# GD32A72_A74x register map
File version: 1.0
CPU: CM7 r2p1, little endian, MPU, FPU, DSP, 4 interrupt priority bits
Registers are 32-bit, read-write, reset 0x0 unless marked. A register's access mark holds for its fields unless they carry their own. Offsets are from the block's base; [hi:lo] are bit positions; {n}, {i} and the like mark numbered series; 'fields as' and 'values as' point back to an identical list.

## CAN0 — Controller area network
Base 0x40018000
Same registers: CAN1 0x40019000, CAN2 0x4001A000
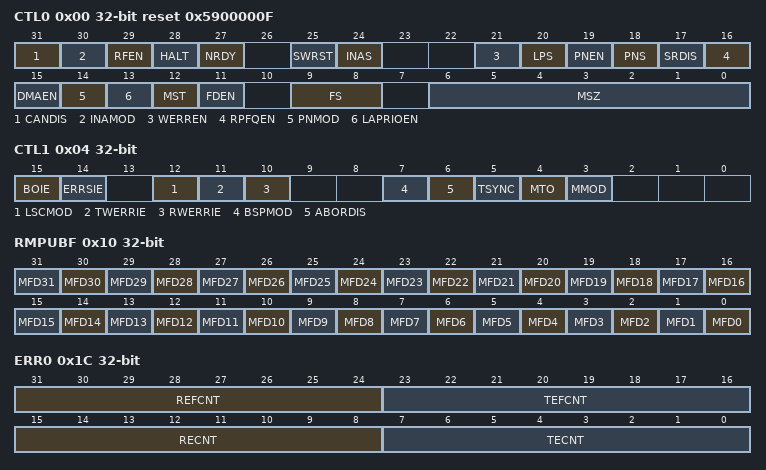
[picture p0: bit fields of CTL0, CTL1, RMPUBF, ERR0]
0x00 CTL0 access per field reset 0x5900000F — Control register 0
  [31] CANDIS rw — CAN disable
  [30] INAMOD rw — Inactive mode enable
  [29] RFEN rw — Rx FIFO enable
  [28] HALT rw — Halt CAN
  [27] NRDY ro — Not ready
  [25] SWRST rw — Software reset
  [24] INAS ro — Inactive mode state
  [21] WERREN rw — Error warning enable
  [20] LPS ro — Low power state
  [19] PNEN rw — Pretended Networking mode enable
  [18] PNS ro — Pretended Networking state
  [17] SRDIS rw — Self reception disable
  [16] RPFQEN rw — Rx private filters enable / Rx mailbox queue enable
  [15] DMAEN rw — DMA enable
  [14] PNMOD rw — Pretended Networking mode selection
  [13] LAPRIOEN rw — Local arbitration priority enable
  [12] MST rw — Mailbox stop transmission
  [11] FDEN rw — CAN FD operation enable
  [9:8] FS rw — Format selection
  [6:0] MSZ rw — Memory size
0x04 CTL1 — Control register 1
  [15] BOIE — Bus off interrupt enable
  [14] ERRSIE — Error summary interrupt enable
  [12] LSCMOD — Loopback and silent communication mode
  [11] TWERRIE — Tx error warning interrupt enable
  [10] RWERRIE — Rx error warning interrupt enable
  [7] BSPMOD — Bit sampling mode
  [6] ABORDIS — Automatic Bus off recovery not enable
  [5] TSYNC — Time synchronization enable
  [4] MTO — Mailbox transmission order
  [3] MMOD — Monitor mode
0x08 TIMER
  [15:0] CNT — Counter value
0x10 RMPUBF — Receive mailbox public filter register
  [n] MFD{n} (n=0..31) — Mailbox filter data {n}
0x1C ERR0 — Error register 0
  [31:24] REFCNT — Receive error counter for data phase of FD frames with BRS bit set
  [23:16] TEFCNT — Transmit error count for the data phase of FD frames with BRS bit set
  [15:8] RECNT — Receive error count defined by the CAN standard
  [7:0] TECNT — Transmit error count defined by the CAN standard
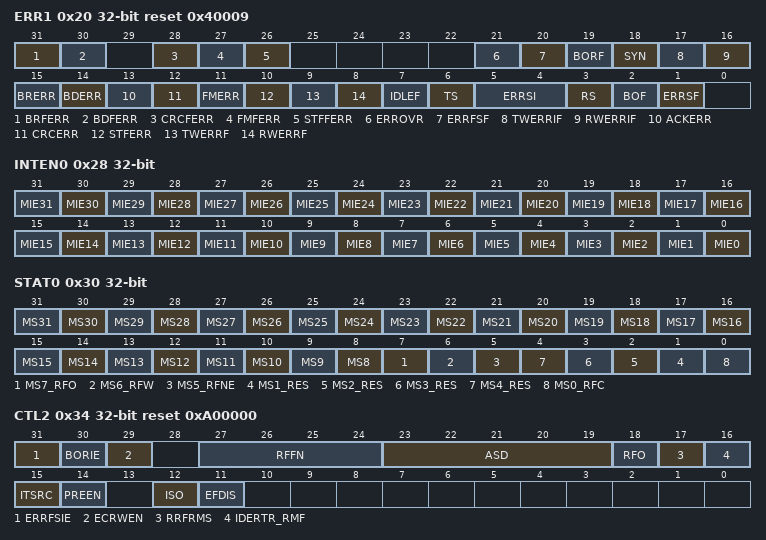
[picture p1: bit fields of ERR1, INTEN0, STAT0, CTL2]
0x20 ERR1 access per field reset 0x40009 — Error register 1
  [31] BRFERR rw — Bit recessive error in data phase of FD frames with the BRS bit set
  [30] BDFERR rw — Bit dominant error in data phase of FD frames with the BRS bit set
  [28] CRCFERR rw — CRC error in data phase of FD frames with the BRS bit set
  [27] FMFERR rw — Form error in data phase of FD frames with the BRS bit set
  [26] STFFERR rw — Stuff error in data phase of FD frames with the BRS bit set
  [21] ERROVR rw — Error overrun
  [20] ERRFSF rw — Error summary flag for data phase of FD frames with BRS bit set
  [19] BORF rw — Bus off recovery flag
  [18] SYN ro — Synchronization flag
  [17] TWERRIF rw — Tx error warning interrupt flag
  [16] RWERRIF rw — Rx error warning interrupt flag
  [15] BRERR rw — Bit recessive error for all format frames
  [14] BDERR rw — Bit dominant error for all format frames
  [13] ACKERR rw — ACK error
  [12] CRCERR rw — CRC error
  [11] FMERR rw — Form error
  [10] STFERR rw — Stuff error
  [9] TWERRF ro — Tx error warning flag
  [8] RWERRF ro — Rx error warning flag
  [7] IDLEF ro — IDLE flag
  [6] TS ro — Transmitting state
  [5:4] ERRSI ro — Error state indicator
  [3] RS ro — Receiving state
  [2] BOF rw — Bus off flag
  [1] ERRSF rw — Error summary flag
0x28 INTEN0 — Interrupt enable register 0
  [n] MIE{n} (n=0..31) — Message transmission and reception interrupt enable {n}
0x30 STAT0 — Status register 0
  [n] MS{n} (n=8..31) — Mailbox {n} state
  [7] MS7_RFO — Mailbox 7 state / Rx FIFO overflow
  [6] MS6_RFW — Mailbox 6 state / Rx FIFO warning
  [5] MS5_RFNE — Mailbox 5 state / Rx FIFO not empty
  [n] MS{n}_RES (n=1..4) — Mailbox {n} state / Reserved
  [0] MS0_RFC — Mailbox 0 state / Clear Rx FIFO bit
0x34 CTL2 reset 0xA00000 — Control register 2
  [31] ERRFSIE — Error summary interrupt enable bit for data phase of FD frames with BRS bit set
  [30] BORIE — Bus off recovery interrupt enable
  [29] ECRWEN — CAN_MERRCTL register write access enable
  [27:24] RFFN — Rx FIFO filter number
  [23:19] ASD — Arbitration start delay
  [18] RFO — Receive filter order
  [17] RRFRMS — Remote request frame is stored
  [16] IDERTR_RMF — IDE and RTR field filter type for Rx mailbox reception
  [15] ITSRC — Internal counter source
  [14] PREEN — Protocol exception detection enable by CAN standard
  [12] ISO — ISO CAN FD
  [11] EFDIS — Edge filtering disable
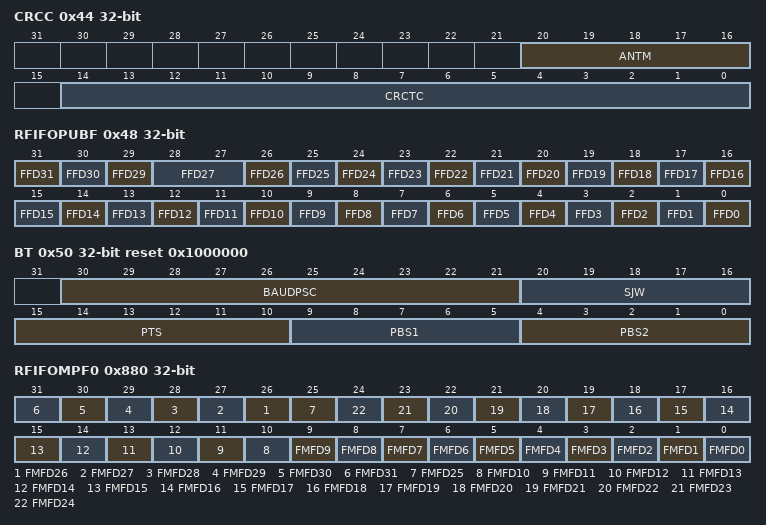
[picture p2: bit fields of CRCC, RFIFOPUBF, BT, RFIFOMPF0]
0x44 CRCC ro — CRC for classical frame register
  [20:16] ANTM — Associated number of mailbox for transmitting the CRCTC[14:0] value
  [14:0] CRCTC — Transmitted CRC value for classical frames
0x48 RFIFOPUBF — Receive FIFO public filter register
  [31] FFD31 — Rx FIFO filter data 31
  [30] FFD30 — Rx FIFO filter data 30
  [29] FFD29 — Rx FIFO filter data 29
  [28:27] FFD27 — Rx FIFO filter data 28
  [n] FFD{n} (n=0..26) — Rx FIFO filter data {n+1}
0x4C RFIFOIFMN ro — Receive FIFO identifier filter matching number register
  [8:0] IDFMN — Identifier filter matching number
0x50 BT reset 0x1000000 — Bit timing register
  [30:21] BAUDPSC — Baud rate prescaler
  [20:16] SJW — Resynchronization jump width
  [15:10] PTS — Propagation time segment
  [9:5] PBS1 — Phase buffer segment 1
  [4:0] PBS2 — Phase buffer segment 2
0x880 RFIFOMPF0 — Receive FIFO/mailbox private filter 0 register
  [n] FMFD{n} (n=26..31) — FIFO/mailbox filter data {n}
  [25] FMFD25 — FIFO/mailbox filter data 27
  [n] FMFD{n} (n=0..24) — FIFO/mailbox filter data {n}
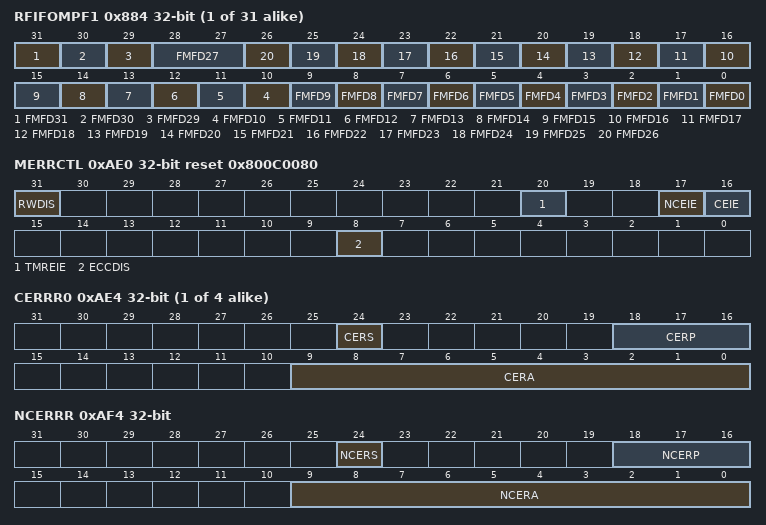
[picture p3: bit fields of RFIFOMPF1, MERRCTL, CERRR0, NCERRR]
{0x880+4i} RFIFOMPF{i} (i=1..31) — Receive FIFO/mailbox private filter {i} register
  [31] FMFD31 — FIFO/mailbox filter data 31
  [30] FMFD30 — FIFO/mailbox filter data 30
  [29] FMFD29 — FIFO/mailbox filter data 29
  [28:27] FMFD27 — FIFO/mailbox filter data 28
  [n] FMFD{n} (n=0..26) — FIFO/mailbox filter data {n+1}
0xAE0 MERRCTL reset 0x800C0080 — Memory error control register
  [31] RWDIS — CAN_MERRCTL register write access disable
  [20] TMREIE — TMR error interrupt enable
  [17] NCEIE — Noncorrectable error interrupt enable
  [16] CEIE — Correctable error interrupt enable
  [8] ECCDIS — Disable ECC
{0xAE4+4i} CERRR{i} access per field (i=0..3) — Correctable error record register {i}
  [24] CERS rw — Correctable error record status
  [18:16] CERP ro — Correctable error record access process
  [9:0] CERA ro — Correctable error record address
0xAF4 NCERRR access per field — Noncorrectable error record register
  [24] NCERS rw — Noncorrectable error record status
  [18:16] NCERP ro — Noncorrectable error record access process
  [9:0] NCERA ro — Noncorrectable error record address
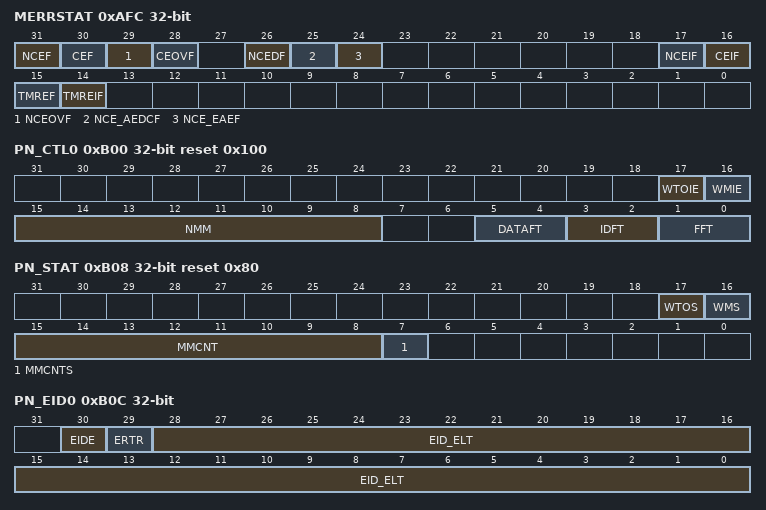
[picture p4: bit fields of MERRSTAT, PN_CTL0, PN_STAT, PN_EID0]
0xAFC MERRSTAT access per field — Memory error status register
  [31] NCEF rw — Noncorrectable error flag
  [30] CEF rw — Correctable error flag
  [29] NCEOVF rw — Noncorrectable error overflow flag
  [28] CEOVF rw — Correctable error overflow flag
  [26] NCEDF rw — Noncorrectable double bit error flag
  [25] NCE_AEDCF rw — Noncorrectable address EDC error flag
  [24] NCE_EAEF rw — Noncorrectable ECC after EDC error flag
  [17] NCEIF rw — Noncorrectable error interrupt flag
  [16] CEIF rw — Correctable error interrupt flag
  [15] TMREF rw — TMR error flag
  [14] TMREIF ro — TMR error interrupt flag
0xB00 PN_CTL0 reset 0x100 — Pretended Networking mode control register 0
  [17] WTOIE — Wakeup timeout interrupt enable
  [16] WMIE — Wakeup match interrupt enable
  [15:8] NMM — Number of messages matching times
  [5:4] DATAFT — DATA field filtering type in Pretended Networking mode
  [3:2] IDFT — ID field filtering type in Pretended Networking mode
  [1:0] FFT — Frame filtering type in Pretended Networking mode
0xB04 PN_TO — Pretended Networking mode timeout register
  [15:0] WTO — Wakeup timeout
0xB08 PN_STAT access per field reset 0x80 — Pretended Networking mode status register
  [17] WTOS rw — Wakeup timeout flag status
  [16] WMS rw — Wakeup match flag status
  [15:8] MMCNT ro — Matching message counter in Pretended Networking mode
  [7] MMCNTS ro — Matching message counter state
0xB0C PN_EID0 — Pretended Networking mode expected identifier 0 register
  [30] EIDE — Expected IDE in Pretended Networking mode
  [29] ERTR — Expected RTR in Pretended Networking mode
  [28:0] EID_ELT — Expected ID field / expected ID low threshold in Pretended Networking mode
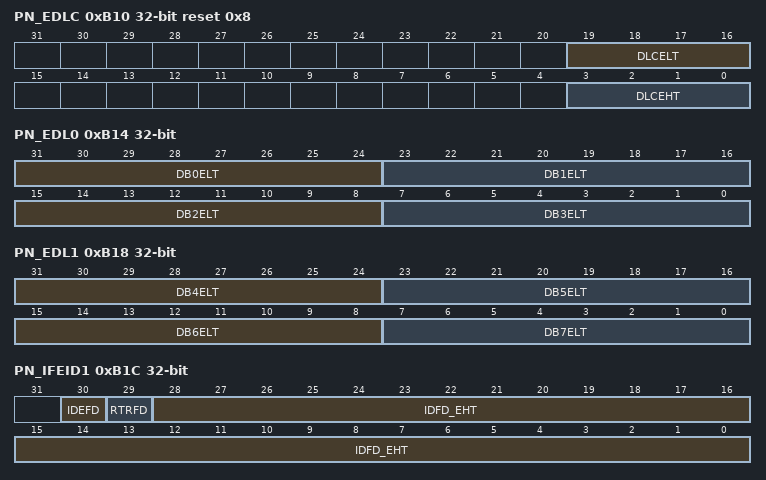
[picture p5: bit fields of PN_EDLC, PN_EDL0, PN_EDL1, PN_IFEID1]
0xB10 PN_EDLC reset 0x8 — Pretended Networking mode expected DLC register
  [19:16] DLCELT — DLC expected low threshold in Pretended Networking mode
  [3:0] DLCEHT — DLC expected high threshold in Pretended Networking mode
0xB14 PN_EDL0 — Pretended Networking mode expected data low 0 register
  [31-8n:24-8n] DB{n}ELT (n=0..3) — Data byte {n} expected low threshold in Pretended Networking mode
0xB18 PN_EDL1 — Pretended Networking mode expected data low 1 register
  [63-8n:56-8n] DB{n}ELT (n=4..7) — Data byte {n} expected low threshold in Pretended Networking mode
0xB1C PN_IFEID1 — Pretended Networking mode identifier filter / expected identifier 1 register
  [30] IDEFD — IDE filter data in Pretended Networking mode
  [29] RTRFD — RTR filter data in Pretended Networking mode
  [28:0] IDFD_EHT — ID filter data / ID expected high threshold in Pretended Networking mode
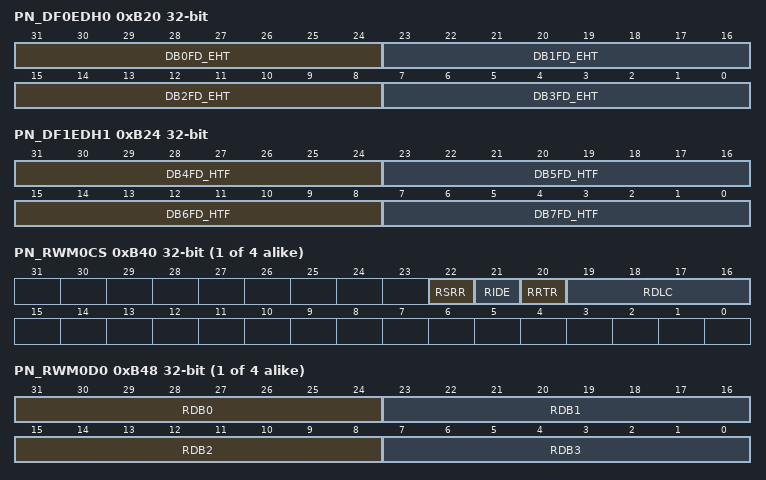
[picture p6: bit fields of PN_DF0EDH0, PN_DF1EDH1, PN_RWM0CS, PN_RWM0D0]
0xB20 PN_DF0EDH0 — Pretended Networking mode data 0 filter / expected data high 0 register
  [31:24] DB0FD_EHT — Data byte 0 filter data / Data byte 0 expected high threshold in Pretended Networking mode
  [23:16] DB1FD_EHT — Data byte 1 filter data / Data byte 1 expected high threshold in Pretended Networking mode
  [15:8] DB2FD_EHT — Data byte 2 filter data / Data byte 2 expected high threshold in Pretended Networking mode
  [7:0] DB3FD_EHT — Data byte 3 filter data / Data byte 2 expected high threshold in Pretended Networking mode
0xB24 PN_DF1EDH1 — Pretended Networking mode data 1 filter / expected data high 1 register
  [63-8n:56-8n] DB{n}FD_HTF (n=4..7) — Data byte {n} filter data / Data byte {n} expected high threshold in Pretended Networking mode
{0xB40+0x10*i} PN_RWM{i}CS ro (i=0..3) — Pretended Networking mode received wakeup mailbox {i} control status information register
  [22] RSRR — Received SRR bit
  [21] RIDE — Received IDE bit
  [20] RRTR — Received RTR bit
  [19:16] RDLC — Received DLC bits
{0xB44+0x10*i} PN_RWM{i}I ro (i=0..3) — Pretended Networking mode received wakeup mailbox {i} identifier register
  [28:0] RID — Received ID bits
{0xB48+0x10*i} PN_RWM{i}D0 ro (i=0..3) — Pretended Networking mode received wakeup mailbox {i} data 0 register
  [31-8n:24-8n] RDB{n} (n=0..3) — Received data byte {n}
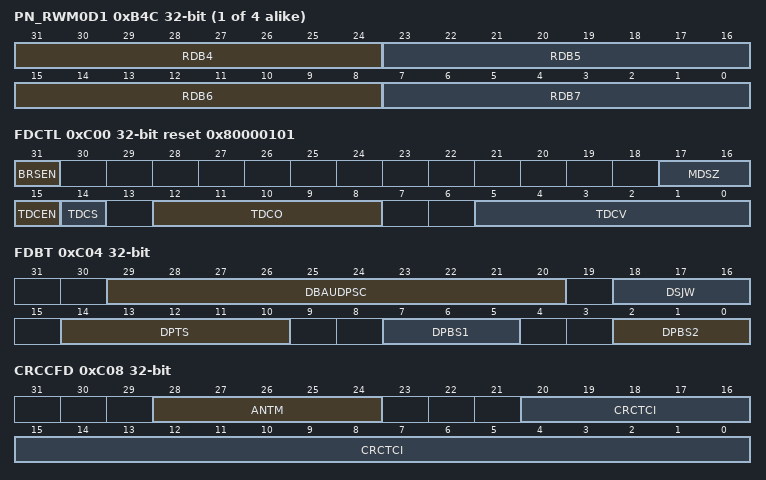
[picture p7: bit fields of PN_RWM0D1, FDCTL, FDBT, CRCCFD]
{0xB4C+0x10*i} PN_RWM{i}D1 ro (i=0..3) — Pretended Networking mode received wakeup mailbox {i} data 1 register
  [63-8n:56-8n] RDB{n} (n=4..7) — Received data byte {n}
0xC00 FDCTL access per field reset 0x80000101 — FD control register
  [31] BRSEN rw — Bit rate of data switch enable
  [17:16] MDSZ rw — Mailbox data size
  [15] TDCEN rw — Transmitter delay compensation enable
  [14] TDCS rw — Transmitter delay compensation status
  [12:8] TDCO rw — Transmitter delay compensation offset
  [5:0] TDCV ro — Transmitter delay compensation value
0xC04 FDBT — FD bit timing register
  [29:20] DBAUDPSC — Baud rate prescaler for data bit time
  [18:16] DSJW — Resynchronization jump width for data bit time
  [14:10] DPTS — Propagation time segment for data bit time
  [7:5] DPBS1 — Phase buffer segment 1 for data bit time
  [2:0] DPBS2 — Phase buffer segment 2 for data bit time
0xC08 CRCCFD ro — CRC for classical and FD frame register
  [28:24] ANTM — Associated number of mailbox for transmitting the CRCTCI[20:0] value
  [20:0] CRCTCI — Transmitted CRC value for classical and ISO / non-ISO FD frames

## CAN3 — Controller area network
Base 0x4001B000
Same registers: CAN4 0x4001C000, CAN5 0x4001D000
Registers as CAN0; these are added or differ:
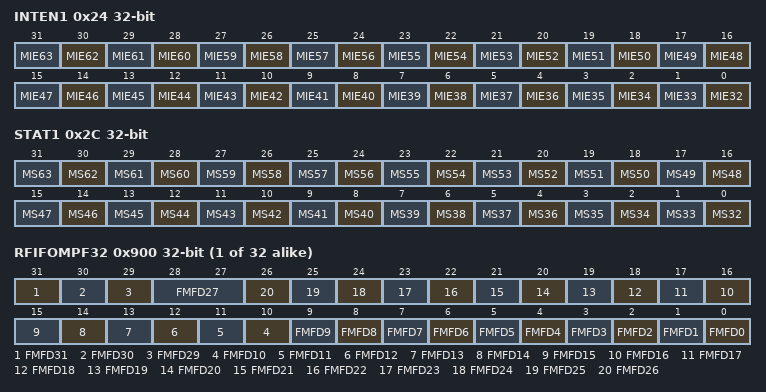
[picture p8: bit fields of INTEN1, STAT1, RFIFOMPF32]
0x24 INTEN1 — Interrupt enable register 1
  [n-32] MIE{n} (n=32..63) — Message transmission and reception interrupt enable {n}
0x2C STAT1 — Status register 1
  [n-32] MS{n} (n=32..63) — Mailbox {n} state
{0x880+4i} RFIFOMPF{i} (i=32..63) — Receive FIFO/mailbox private filter {i} register
  fields as CAN0.RFIFOMPF1

## CAN6 — Controller area network
Base 0x4001E000
Same registers: CAN7 0x4001F000
Registers as CAN3; these are added or differ:
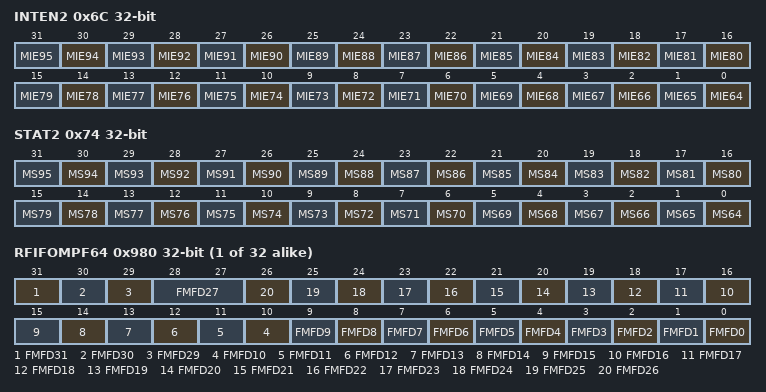
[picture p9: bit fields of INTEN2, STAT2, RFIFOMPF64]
0x6C INTEN2 — Interrupt enable register 2
  [n-64] MIE{n} (n=64..95) — Message transmission and reception interrupt enable {n}
0x74 STAT2 — Status register 2
  [n-64] MS{n} (n=64..95) — Mailbox {n} state
{0x880+4i} RFIFOMPF{i} (i=64..95) — Receive FIFO/mailbox private filter {i} register
  fields as CAN0.RFIFOMPF1
